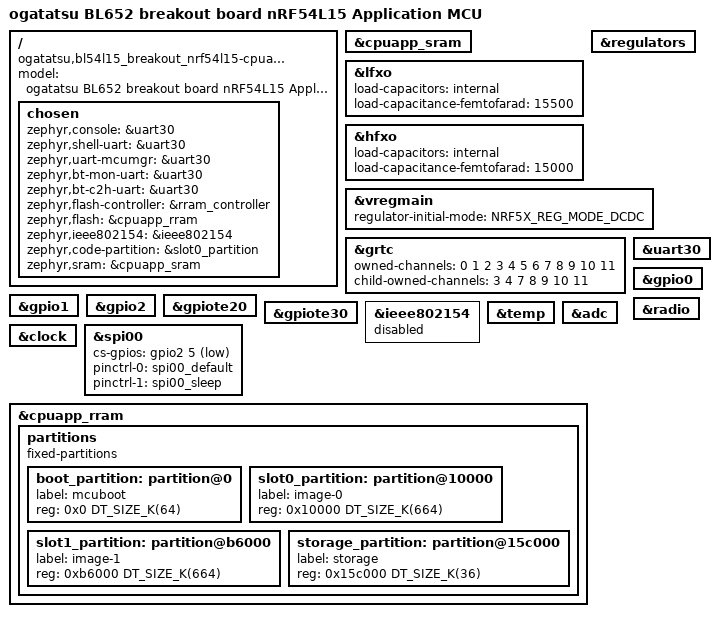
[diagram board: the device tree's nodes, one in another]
/*
 * Copyright (c) 2024 Nordic Semiconductor ASA
 * Copyright (c) 2025 Jamie M.
 *
 * SPDX-License-Identifier: Apache-2.0
 */

/dts-v1/;

#include <nordic/nrf54l15_cpuapp.dtsi>
#include "bl54l15_breakout_common.dtsi"

/ {
	compatible = "ogatatsu,bl54l15_breakout_nrf54l15-cpuapp";
	model = "ogatatsu BL652 breakout board nRF54L15 Application MCU";

	chosen {
#if 1
		zephyr,console = &uart30;
		zephyr,shell-uart = &uart30;
		zephyr,uart-mcumgr = &uart30;
		zephyr,bt-mon-uart = &uart30;
		zephyr,bt-c2h-uart = &uart30;
#else
		zephyr,console = &uart20;
		zephyr,shell-uart = &uart20;
		zephyr,uart-mcumgr = &uart20;
		zephyr,bt-mon-uart = &uart20;
		zephyr,bt-c2h-uart = &uart20;
#endif
		zephyr,flash-controller = &rram_controller;
		zephyr,flash = &cpuapp_rram;
		zephyr,ieee802154 = &ieee802154;
		zephyr,code-partition = &slot0_partition;
		zephyr,sram = &cpuapp_sram;
	};
};

&cpuapp_sram {
	status = "okay";
};

&lfxo {
	load-capacitors = "internal";
	load-capacitance-femtofarad = <15500>;
};

&hfxo {
	load-capacitors = "internal";
	load-capacitance-femtofarad = <15000>;
};

&regulators {
	status = "okay";
};

&vregmain {
	status = "okay";
	regulator-initial-mode = <NRF5X_REG_MODE_DCDC>;
};

&grtc {
	owned-channels = <0 1 2 3 4 5 6 7 8 9 10 11>;
	/* Channels 7-11 reserved for Zero Latency IRQs, 3-4 for FLPR */
	child-owned-channels = <3 4 7 8 9 10 11>;
	status = "okay";
};

#if 1
&uart30 {
	status = "okay";
};
#else
&uart20 {
	status = "okay";
};
#endif

&gpio0 {
	status = "okay";
};

&gpio1 {
	status = "okay";
};

&gpio2 {
	status = "okay";
};

&gpiote20 {
	status = "okay";
};

&gpiote30 {
	status = "okay";
};

&radio {
	status = "okay";
};

&ieee802154 {
	status = "disabled";
};

&temp {
	status = "okay";
};

&clock {
	status = "okay";
};

&spi00 {
	status = "okay";
	cs-gpios = <&gpio2 5 GPIO_ACTIVE_LOW>;
	pinctrl-0 = <&spi00_default>;
	pinctrl-1 = <&spi00_sleep>;
	pinctrl-names = "default", "sleep";
};

&adc {
	status = "okay";
};

&cpuapp_rram {
	partitions {
		compatible = "fixed-partitions";
		#address-cells = <1>;
		#size-cells = <1>;

		boot_partition: partition@0 {
			label = "mcuboot";
			reg = <0x0 DT_SIZE_K(64)>;
		};

		slot0_partition: partition@10000 {
			label = "image-0";
			reg = <0x10000 DT_SIZE_K(664)>;
		};

		slot1_partition: partition@b6000 {
			label = "image-1";
			reg = <0xb6000 DT_SIZE_K(664)>;
		};

		storage_partition: partition@15c000 {
			label = "storage";
			reg = <0x15c000 DT_SIZE_K(36)>;
		};
	};
};
